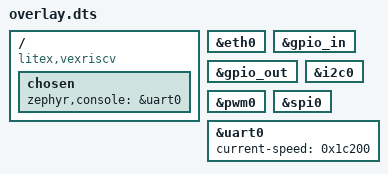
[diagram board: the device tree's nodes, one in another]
/ {
	compatible = "litex,vexriscv";
	chosen {
		zephyr,console = &uart0;
	};
};
&eth0{
	status = "okay";
};
&gpio_in{
	status = "okay";
};
&gpio_out{
	status = "okay";
};
&i2c0{
	status = "okay";
};
&pwm0{
	status = "okay";
};
&spi0{
	status = "okay";
};
&uart0{
	status = "okay";
	current-speed = < 0x1c200 >;
};
